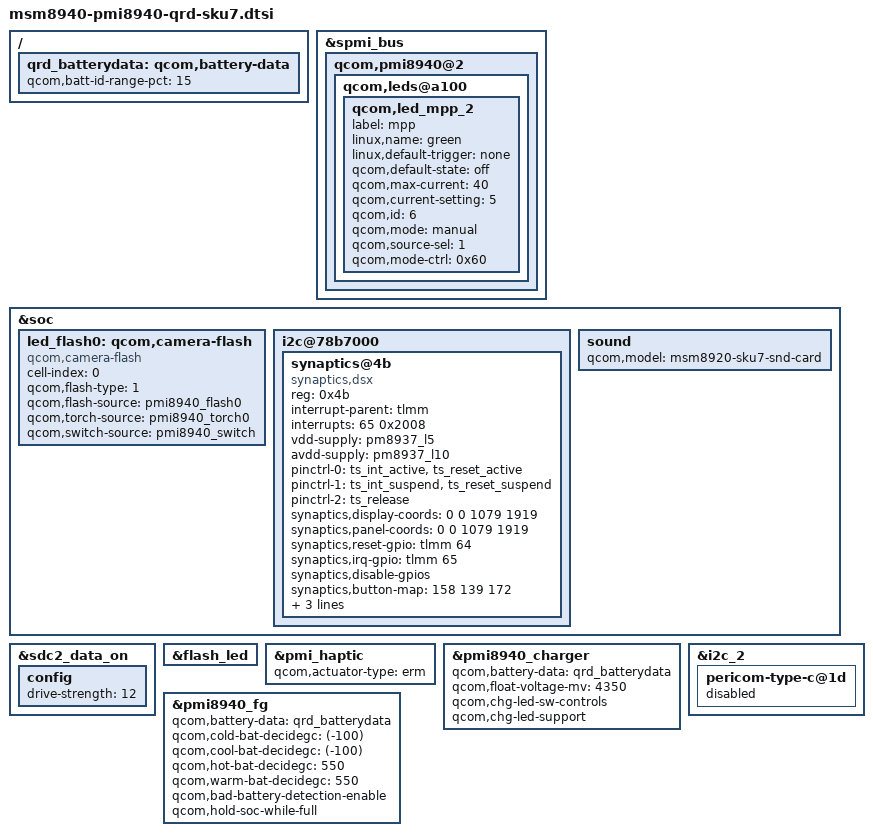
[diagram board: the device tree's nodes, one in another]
/*
 * Copyright (c) 2016, The Linux Foundation. All rights reserved.
 *
 * This program is free software; you can redistribute it and/or modify
 * it under the terms of the GNU General Public License version 2 and
 * only version 2 as published by the Free Software Foundation.
 *
 * This program is distributed in the hope that it will be useful,
 * but WITHOUT ANY WARRANTY; without even the implied warranty of
 * MERCHANTABILITY or FITNESS FOR A PARTICULAR PURPOSE.  See the
 * GNU General Public License for more details.
 */

#include "msm-pmi8940.dtsi"
#include "msm8937-qrd.dtsi"
#include "msm8937-mdss-panels.dtsi"

/ {
	qrd_batterydata: qcom,battery-data {
		qcom,batt-id-range-pct = <15>;
		#include "batterydata-qrd-sku2-4v35-2590mah.dtsi"
	};
};

&spmi_bus {
	qcom,pmi8940@2 {
		qcom,leds@a100 {
			status = "okay";
			qcom,led_mpp_2 {
				label = "mpp";
				linux,name = "green";
				linux,default-trigger = "none";
				qcom,default-state = "off";
				qcom,max-current = <40>;
				qcom,current-setting = <5>;
				qcom,id = <6>;
				qcom,mode = "manual";
				qcom,source-sel = <1>;
				qcom,mode-ctrl = <0x60>;
			};
		};
	};
};

&soc {
	led_flash0: qcom,camera-flash {
		cell-index = <0>;
		compatible = "qcom,camera-flash";
		qcom,flash-type = <1>;
		qcom,flash-source = <&pmi8940_flash0>;
		qcom,torch-source = <&pmi8940_torch0>;
		qcom,switch-source = <&pmi8940_switch>;
	};
	i2c@78b7000 {
		status = "ok";
		synaptics@4b {
			compatible = "synaptics,dsx";
			reg = <0x4b>;
			interrupt-parent = <&tlmm>;
			interrupts = <65 0x2008>;
			vdd-supply = <&pm8937_l5>;
			avdd-supply = <&pm8937_l10>;
			pinctrl-names = "pmx_ts_active","pmx_ts_suspend",
				"pmx_ts_release";
			pinctrl-0 = <&ts_int_active &ts_reset_active>;
			pinctrl-1 = <&ts_int_suspend &ts_reset_suspend>;
			pinctrl-2 = <&ts_release>;
			synaptics,display-coords = <0 0 1079 1919>;
			synaptics,panel-coords = <0 0 1079 1919>;
			synaptics,reset-gpio = <&tlmm 64 0x00>;
			synaptics,irq-gpio = <&tlmm 65 0x2008>;
			synaptics,disable-gpios;
			synaptics,button-map = <158 139 172>;
			synaptics,resume-in-workqueue;
			/* Underlying clocks used by secure touch */
			clock-names = "iface_clk", "core_clk";
			clocks = <&clock_gcc clk_gcc_blsp1_ahb_clk>,
				<&clock_gcc clk_gcc_blsp1_qup3_i2c_apps_clk>;
		};
	};
};

&sdc2_data_on {
	config {
		drive-strength = <12>;
	};
};

&flash_led {
	/delete-node/ qcom,flash_1;
	/delete-node/ qcom,torch_1;
};

&pmi_haptic {
	qcom,actuator-type = "erm";
};

&pmi8940_charger {
	qcom,battery-data = <&qrd_batterydata>;
	qcom,float-voltage-mv = <4350>;
	qcom,chg-led-sw-controls;
	qcom,chg-led-support;
	status = "okay";
};

&pmi8940_fg {
	qcom,battery-data = <&qrd_batterydata>;
	qcom,cold-bat-decidegc = <(-100)>;
	qcom,cool-bat-decidegc = <(-100)>;
	qcom,hot-bat-decidegc = <550>;
	qcom,warm-bat-decidegc = <550>;
	qcom,bad-battery-detection-enable;
	qcom,hold-soc-while-full;
};

&soc {
	sound {
		qcom,model = "msm8920-sku7-snd-card";
	};
};

&i2c_2 {
	pericom-type-c@1d {
		status="disabled";
	};
};

